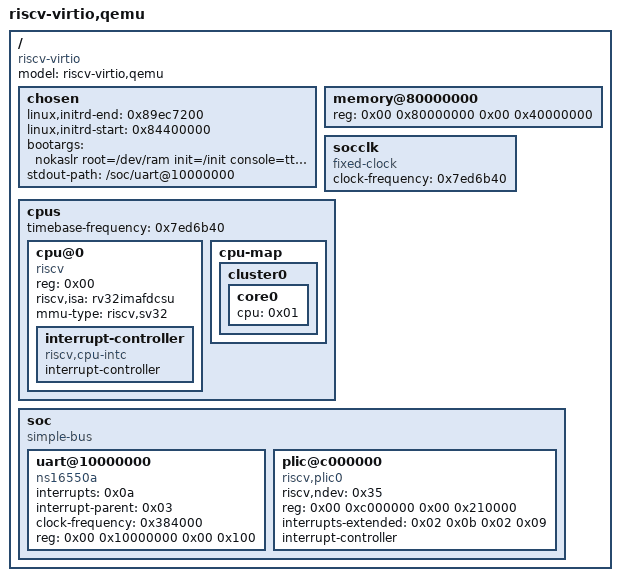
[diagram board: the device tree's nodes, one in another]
/dts-v1/;

/ {
	#address-cells = <0x02>;
	#size-cells = <0x02>;
	compatible = "riscv-virtio";
	model = "riscv-virtio,qemu";

	chosen {
		linux,initrd-end = <0x89ec7200>;
		linux,initrd-start = <0x84400000>;
		bootargs = "nokaslr root=/dev/ram init=/init console=ttyS0,230400n8 earlycon=sbi";
		stdout-path = "/soc/uart@10000000";
	};

	memory@80000000 {
		device_type = "memory";
		reg = <0x00 0x80000000 0x00 0x40000000>;
	};

	socclk {
		compatible = "fixed-clock";
		clock-frequency = <0x7ed6b40>;
		#clock-cells = <0x00>;
	};

	cpus {
		#address-cells = <0x01>;
		#size-cells = <0x00>;
		timebase-frequency = <0x7ed6b40>;

		cpu@0 {
			phandle = <0x01>;
			device_type = "cpu";
			reg = <0x00>;
			status = "okay";
			compatible = "riscv";
			riscv,isa = "rv32imafdcsu";
			mmu-type = "riscv,sv32";

			interrupt-controller {
				#interrupt-cells = <0x01>;
				interrupt-controller;
				compatible = "riscv,cpu-intc";
				phandle = <0x02>;
			};
		};

		cpu-map {

			cluster0 {

				core0 {
					cpu = <0x01>;
				};
			};
		};
	};

	soc {
		#address-cells = <0x02>;
		#size-cells = <0x02>;
		compatible = "simple-bus";
		ranges;

		uart@10000000 {
			interrupts = <0x0a>;
			interrupt-parent = <0x03>;
			clock-frequency = <0x384000>;
			reg = <0x00 0x10000000 0x00 0x100>;
			compatible = "ns16550a";
		};

		plic@c000000 {
			phandle = <0x03>;
			riscv,ndev = <0x35>;
			reg = <0x00 0xc000000 0x00 0x210000>;
			interrupts-extended = <0x02 0x0b 0x02 0x09>;
			interrupt-controller;
			compatible = "riscv,plic0";
			#interrupt-cells = <0x01>;
			#address-cells = <0x00>;
		};
	};
};
